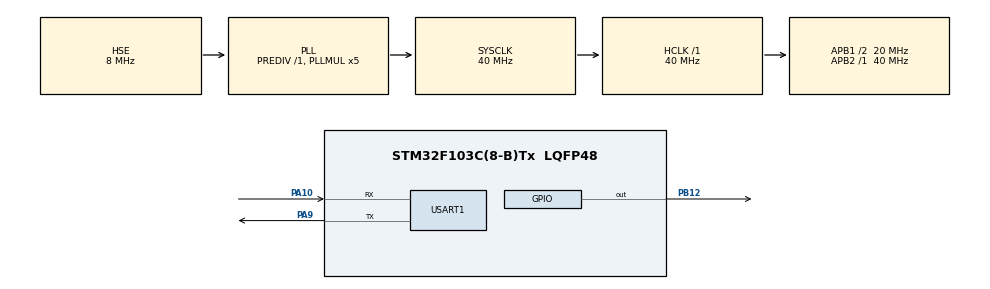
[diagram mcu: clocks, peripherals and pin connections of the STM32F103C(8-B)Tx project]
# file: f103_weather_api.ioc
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Mcu.Family=STM32F1
Mcu.Name=STM32F103C(8-B)Tx
Mcu.Package=LQFP48
NVIC.PriorityGroup=NVIC_PRIORITYGROUP_4
NVIC.USART1_IRQn=true\:0\:0\:false\:true\:true\:1\:true\:true
PA10.Mode=Asynchronous
PA10.Signal=USART1_RX
PA13.Mode=Trace_Asynchronous_SW
PA13.Signal=SYS_JTMS-SWDIO
PA14.Mode=Trace_Asynchronous_SW
PA14.Signal=SYS_JTCK-SWCLK
PA9.Mode=Asynchronous
PA9.Signal=USART1_TX
PB12.Signal=GPIO_Output
PB3.Mode=Trace_Asynchronous_SW
PB3.Signal=SYS_JTDO-TRACESWO
PD0-OSC_IN.Mode=HSE-External-Oscillator
PD0-OSC_IN.Signal=RCC_OSC_IN
PD1-OSC_OUT.Mode=HSE-External-Oscillator
PD1-OSC_OUT.Signal=RCC_OSC_OUT
ProjectManager.HeapSize=0x200
ProjectManager.StackSize=0x400
ProjectManager.TargetToolchain=MDK-ARM V5.27
RCC.AHBFreq_Value=40000000
RCC.APB1CLKDivider=RCC_HCLK_DIV2
RCC.APB1Freq_Value=20000000
RCC.APB1TimFreq_Value=40000000
RCC.APB2Freq_Value=40000000
RCC.APB2TimFreq_Value=40000000
RCC.HCLKFreq_Value=40000000
RCC.PLLMUL=RCC_PLL_MUL5
RCC.PLLSourceVirtual=RCC_PLLSOURCE_HSE
RCC.SYSCLKFreq_VALUE=40000000
RCC.SYSCLKSource=RCC_SYSCLKSOURCE_PLLCLK
RCC.USBFreq_Value=40000000
USART1.VirtualMode=VM_ASYNC
board=custom

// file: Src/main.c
/* USER CODE BEGIN Header */
/**
	* Weather API test program.
	*
	* main.c
	*
  * MCU: STM32F103C8T6
	* IDE: Keil uVision V5.29.0.0 & STM32CubeMX 5.6.0
	* HCLK : 40 MHz
	*
  * Wifi Module : ESP8266-01
	* 		AT version: 1.3.0.0
	* 		SDK version: 2.0.0
	*
  * Copyright 2020 Gachon University, TAKE OUT, Development Group, electric engineering, Seongwook Kang.
  */
/* USER CODE END Header */

#include "main.h"
#include "usart.h"
#include "gpio.h"

/* USER CODE BEGIN Includes */
#include <string.h>

/* USER CODE END Includes */

/* USER CODE BEGIN PV */
extern uint8_t rx_Buffer;
/* USER CODE END PV */

void SystemClock_Config(void);
static void MX_NVIC_Init(void);
/* USER CODE BEGIN PFP */
extern void getWeather(void);
/* USER CODE END PFP */

int main(void)
{

  /* MCU Configuration--------------------------------------------------------*/

  /* Reset of all peripherals, Initializes the Flash interface and the Systick. */
  HAL_Init();

  /* Configure the system clock */
  SystemClock_Config();

  /* Initialize all configured peripherals */
  MX_GPIO_Init();
  MX_USART1_UART_Init();

  /* Initialize interrupts */
  MX_NVIC_Init();
  /* USER CODE BEGIN 2 */
	HAL_UART_Receive_IT(&huart1, &rx_Buffer, 1);

  /* USER CODE END 2 */

  /* Infinite loop */
  /* USER CODE BEGIN WHILE */
  while (1)
  {
		getWeather();
    /* USER CODE END WHILE */

  }
}

void SystemClock_Config(void)
{
  RCC_OscInitTypeDef RCC_OscInitStruct = {0};
  RCC_ClkInitTypeDef RCC_ClkInitStruct = {0};

  /** Initializes the CPU, AHB and APB busses clocks
  */
  RCC_OscInitStruct.OscillatorType = RCC_OSCILLATORTYPE_HSE;
  RCC_OscInitStruct.HSEState = RCC_HSE_ON;
  RCC_OscInitStruct.HSEPredivValue = RCC_HSE_PREDIV_DIV1;
  RCC_OscInitStruct.HSIState = RCC_HSI_ON;
  RCC_OscInitStruct.PLL.PLLState = RCC_PLL_ON;
  RCC_OscInitStruct.PLL.PLLSource = RCC_PLLSOURCE_HSE;
  RCC_OscInitStruct.PLL.PLLMUL = RCC_PLL_MUL5;
  if (HAL_RCC_OscConfig(&RCC_OscInitStruct) != HAL_OK)
  {
    Error_Handler();
  }
  /** Initializes the CPU, AHB and APB busses clocks
  */
  RCC_ClkInitStruct.ClockType = RCC_CLOCKTYPE_HCLK|RCC_CLOCKTYPE_SYSCLK
                              |RCC_CLOCKTYPE_PCLK1|RCC_CLOCKTYPE_PCLK2;
  RCC_ClkInitStruct.SYSCLKSource = RCC_SYSCLKSOURCE_PLLCLK;
  RCC_ClkInitStruct.AHBCLKDivider = RCC_SYSCLK_DIV1;
  RCC_ClkInitStruct.APB1CLKDivider = RCC_HCLK_DIV2;
  RCC_ClkInitStruct.APB2CLKDivider = RCC_HCLK_DIV1;

  if (HAL_RCC_ClockConfig(&RCC_ClkInitStruct, FLASH_LATENCY_1) != HAL_OK)
  {
    Error_Handler();
  }
}

/**
  * @brief NVIC Configuration.
  * @retval None
  */
static void MX_NVIC_Init(void)
{
  /* USART1_IRQn interrupt configuration */
  HAL_NVIC_SetPriority(USART1_IRQn, 0, 0);
  HAL_NVIC_EnableIRQ(USART1_IRQn);
}

void Error_Handler(void)
{
}

/************************ (C) COPYRIGHT STMicroelectronics *****END OF FILE****/
